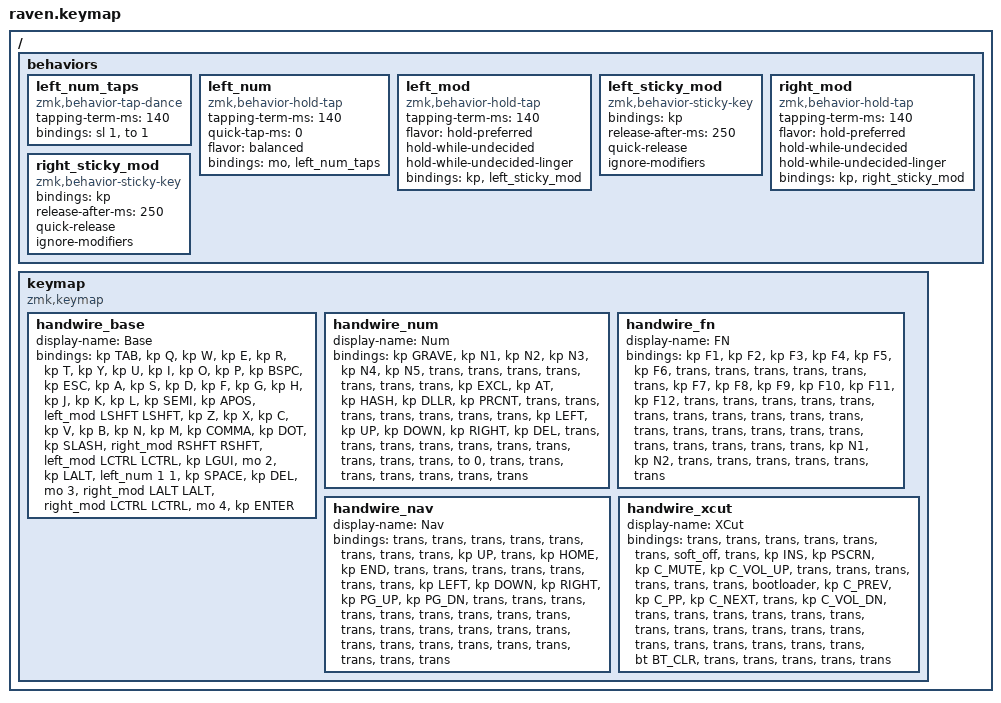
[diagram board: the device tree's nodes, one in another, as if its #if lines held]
#include <behaviors.dtsi>
#include <dt-bindings/zmk/keys.h>
#include <dt-bindings/zmk/bt.h>
#if defined(RAVEN_LEFT_HANDWIRE) || defined(RAVEN_RIGHT_HANDWIRE)
// Shared 4x12 handwire map: left central, right peripheral.
// Layers: Base=0, Num=1, FN=2, Nav=3, XCut=4.
/ {
    behaviors {
        left_num_taps: left_num_taps {
            compatible = "zmk,behavior-tap-dance";
            #binding-cells = <0>;
            tapping-term-ms = <140>;
            bindings = <&sl 1>, <&to 1>;
        };

        left_num: left_num {
            compatible = "zmk,behavior-hold-tap";
            #binding-cells = <2>;
            tapping-term-ms = <140>;
            quick-tap-ms = <0>;
            flavor = "balanced";
            bindings = <&mo>, <&left_num_taps>;
        };

        left_mod: left_mod {
            compatible = "zmk,behavior-hold-tap";
            #binding-cells = <2>;
            tapping-term-ms = <140>;
            flavor = "hold-preferred";
            hold-while-undecided;
            hold-while-undecided-linger;
            bindings = <&kp>, <&left_sticky_mod>;
        };

        left_sticky_mod: left_sticky_mod {
            compatible = "zmk,behavior-sticky-key";
            #binding-cells = <1>;
            bindings = <&kp>;
            release-after-ms = <250>;
            quick-release;
            ignore-modifiers;
        };

        right_mod: right_mod {
            compatible = "zmk,behavior-hold-tap";
            #binding-cells = <2>;
            tapping-term-ms = <140>;
            flavor = "hold-preferred";
            hold-while-undecided;
            hold-while-undecided-linger;
            bindings = <&kp>, <&right_sticky_mod>;
        };
        right_sticky_mod: right_sticky_mod {
            compatible = "zmk,behavior-sticky-key";
            #binding-cells = <1>;
            bindings = <&kp>;
            release-after-ms = <250>;
            quick-release;
            ignore-modifiers;
        };
    };
    keymap {
        compatible = "zmk,keymap";
        handwire_base {
            display-name = "Base";
            bindings = <
                &kp TAB   &kp Q   &kp W   &kp E   &kp R   &kp T     &kp Y   &kp U   &kp I   &kp O   &kp P   &kp BSPC
                &kp ESC   &kp A   &kp S   &kp D   &kp F   &kp G     &kp H   &kp J   &kp K   &kp L   &kp SEMI   &kp APOS
                &left_mod LSHFT LSHFT   &kp Z   &kp X   &kp C   &kp V   &kp B     &kp N   &kp M   &kp COMMA   &kp DOT   &kp SLASH   &right_mod RSHFT RSHFT
                &left_mod LCTRL LCTRL   &kp LGUI   &mo 2   &kp LALT   &left_num 1 1   &kp SPACE     &kp DEL   &mo 3   &right_mod LALT LALT   &right_mod LCTRL LCTRL   &mo 4   &kp ENTER
            >;
        };
        handwire_num {
            display-name = "Num";
            bindings = <
                &kp GRAVE   &kp N1   &kp N2   &kp N3   &kp N4   &kp N5     &trans   &trans   &trans   &trans   &trans   &trans
                &trans   &kp EXCL   &kp AT   &kp HASH   &kp DLLR   &kp PRCNT     &trans   &trans   &trans   &trans   &trans   &trans
                &trans   &kp LEFT   &kp UP   &kp DOWN   &kp RIGHT   &kp DEL     &trans   &trans   &trans   &trans   &trans   &trans
                &trans   &trans   &trans   &trans   &to 0   &trans     &trans   &trans   &trans   &trans   &trans   &trans
            >;
        };
        handwire_fn {
            display-name = "FN";
            bindings = <
                &kp F1   &kp F2   &kp F3   &kp F4   &kp F5   &kp F6     &trans   &trans   &trans   &trans   &trans   &trans
                &kp F7   &kp F8   &kp F9   &kp F10   &kp F11   &kp F12     &trans   &trans   &trans   &trans   &trans   &trans
                &trans   &trans   &trans   &trans   &trans   &trans     &trans   &trans   &trans   &trans   &trans   &trans
                &trans   &trans   &trans   &trans   &kp N1   &kp N2     &trans   &trans   &trans   &trans   &trans   &trans
            >;
        };
        handwire_nav {
            display-name = "Nav";
            bindings = <
                &trans   &trans   &trans   &trans   &trans   &trans     &trans   &trans   &kp UP   &trans   &kp HOME   &kp END
                &trans   &trans   &trans   &trans   &trans   &trans     &trans   &kp LEFT   &kp DOWN   &kp RIGHT   &kp PG_UP   &kp PG_DN
                &trans   &trans   &trans   &trans   &trans   &trans     &trans   &trans   &trans   &trans   &trans   &trans
                &trans   &trans   &trans   &trans   &trans   &trans     &trans   &trans   &trans   &trans   &trans   &trans
            >;
        };
        handwire_xcut {
            display-name = "XCut";
            bindings = <
                &trans   &trans   &trans   &trans   &trans   &trans     &soft_off   &trans   &kp INS   &kp PSCRN   &kp C_MUTE   &kp C_VOL_UP
                &trans   &trans   &trans   &trans   &trans   &trans     &bootloader   &kp C_PREV   &kp C_PP   &kp C_NEXT   &trans   &kp C_VOL_DN
                &trans   &trans   &trans   &trans   &trans   &trans     &trans   &trans   &trans   &trans   &trans   &trans
                &trans   &trans   &trans   &trans   &trans   &trans     &bt BT_CLR   &trans   &trans   &trans   &trans   &trans
            >;
        };
    };
};

#else
//https://zmk.dev/docs/keymaps/behaviors/sticky-key
/ {
    behaviors {
        hid_fwd: hid_fwd {
            compatible = "zmk,behavior-hid-fwd";
            label = "HID_FWD";
            #binding-cells = <0>;
        };
        mt: mod_tap {
            compatible = "zmk,behavior-hold-tap";
            #binding-cells = <2>;
            tapping-term-ms = <140>;
            bindings = <&kp>, <&skq>;
            flavor = "hold-preferred";
            hold-while-undecided;
            hold-while-undecided-linger;  // prevents shift release between hold and sticky
        };

        skq: sticky_key_quick_release {
            compatible = "zmk,behavior-sticky-key";
            #binding-cells = <1>;
            bindings = <&kp>;
            release-after-ms = <250>;
            quick-release;
            ignore-modifiers;
        };

        skl: sticky_key_lazy {
            compatible = "zmk,behavior-sticky-key";
            #binding-cells = <1>;
            bindings = <&kp>;
            release-after-ms = <250>;
            ignore-modifiers;
            lazy;
        };

        win_z: win_z_hold_tap {
            compatible = "zmk,behavior-hold-tap";
            label = "WIN_Z _HOLD_TAP";
            #binding-cells = <2>;
            tapping-term-ms = <140>; //hold timer to send hold key
            quick-tap-ms = <500>; //when tapped within timer, disable hold and send tap; for repeated presses
            require-prior-idle-ms = <250>; //When key press before timer, disable hold
            flavor = "tap-preferred";
            bindings = <&kp>, <&kp>;
        };

        not_so_sticky: not_so_sticky { //useful for combinations
            compatible = "zmk,behavior-sticky-key";
            label = "NOT_SO_STICKY";
            #binding-cells = <1>;
            bindings = <&mo>;
            release-after-ms = <800>;
            ignore-modifiers;
            //no 'quick-release' makes it linger even after a keypress
        };

        td_layer1: tap_dance_layer {
            compatible = "zmk,behavior-tap-dance";
            label = "TAP_DANCE_LAYER";
            #binding-cells = <0>;
            tapping-term-ms = <140>;
            bindings = <&sl 2>, <&to 2>;    // First tap = sticky layer 2, double tap = switch to layer 2
        };

        slmo1: sticky_momentary_layer {
            compatible = "zmk,behavior-hold-tap";
            label = "STICKY_MOMENTARY_LAYER";
            #binding-cells = <2>;
            tapping-term-ms = <140>;
            quick-tap-ms = <0>;
            flavor = "balanced";
            bindings = <&mo>, <&td_layer1>;  // Hold for momentary, tap for tap-dance behavior ex:&slmo 1 2
        };

        td_layer2: tap_dance_layer2 {
            compatible = "zmk,behavior-tap-dance";
            label = "TAP_DANCE_LAYER2";
            #binding-cells = <0>;
            tapping-term-ms = <140>;
            bindings = <&not_so_sticky 3>, <&to 3>;    // First tap = sticky layer 1, double tap = switch to layer 1
        };

        slmo2: sticky_momentary_layer2 {
            compatible = "zmk,behavior-hold-tap";
            label = "STICKY_MOMENTARY_LAYER2";
            #binding-cells = <2>;
            tapping-term-ms = <140>;
            quick-tap-ms = <0>;
            flavor = "balanced";
            bindings = <&mo>, <&td_layer2>;  // Hold for momentary, tap for tap-dance behavior ex:&slmo 1 2
        };

    };
    macros {
        sleep_macro: sleep_macro {
            compatible = "zmk,behavior-macro";
            #binding-cells = <0>;
            bindings
                = <&macro_press &kp LGUI>
                , <&macro_tap &kp X>
                , <&macro_release &kp LGUI>
                , <&macro_tap &kp U>
                , <&macro_tap &kp S>;
        };
    };
    combos {
        compatible = "zmk,combos";
        combo_esc {
            timeout-ms = <50>;
            key-positions = <0 1>; //TAB + Q
            bindings = <&kp ESC>;
            layers = <0 1 2 3 4>;
        };
        combo_capslock {
            timeout-ms = <50>;
            key-positions = <12 13>; // SHIFT + A
            bindings = <&kp CAPSLOCK>;
            layers = <0 1 2 3 4>;
        };
        layer_lock {
            timeout-ms = <50>;
            key-positions = <36 37>;   // ALT + NUM
            bindings = <&tog 2>;       // toggle layer 2
        };
        /*
        spc_del {
            timeout-ms = <50>;
            key-positions = <29 38>;   // B + SPC
            bindings = <&kp DEL>;
        };
        */
        xcut_layer {
            timeout-ms = <250>;
            key-positions = <34 35>;   // SLASH + LSHFT
            bindings = <&mo 5>;
        };

        alt_f4 {
            timeout-ms = <100>;
            require-prior-idle-ms = <100>; // Fix for "sticky" feeling; prevents combo if a key was pressed 150ms before
            key-positions = <36 16 3>;   // ALT + F + E    (ALT F + 4 hehe)
            bindings = <&kp LA(F4)>;  // Alt + F4 https://zmk.dev/docs/keymaps/modifiers
        };
    };

    keymap {
        compatible = "zmk,keymap";
        default_layer {
            display-name = "Base";
            bindings = <
                &kp TAB             &kp Q           &kp W       &kp E       &kp R       &kp T       &kp Y      &kp U        &kp I       &kp O       &kp P       &kp BSPC
                &mt LSHFT LSHFT     &kp A           &kp S       &kp D       &kp F       &kp G       &kp H      &kp J        &kp K       &kp L       &kp SEMI    &kp APOS
                &mt LCTRL LCTRL     &win_z LGUI Z   &kp X       &kp C       &kp V       &kp B       &kp N      &kp M        &kp COMMA   &kp DOT     &kp SLASH   &mt RSHFT RSHFT //used to be "mo 5"
                                                                &kp LALT    &slmo1 2 2  &kp SPACE   &kp DEL    &slmo2 4 4   &kp ENTER
            >;
        };
        // Layer 1 (Activated on Tap) Game layer, unused really. Remove?
        Game_layer {
            display-name = "Game";
            bindings = <
                &kp N1      &kp TAB         &kp Q       &kp W       &kp E       &kp R       &kp Y      &kp U        &kp I       &kp O       &kp P       &kp BSPC
                &kp N2      &kp LSHFT       &kp A       &kp S       &kp D       &kp F       &kp H      &kp J        &kp K       &kp L       &kp SEMI    &kp APOS
                &kp N3      &kp LCTRL       &kp Z       &kp X       &kp C       &kp V       &kp N      &kp M        &kp COMMA   &kp DOT     &kp SLASH   &to 0
                                                        &kp LALT    &mo 2       &kp SPACE   &kp DEL    &mo 4        &kp ENTER
            >;
        };
        // Layer 2 (Activated on hold)
        Num_layer {
            display-name = "Num";
            bindings = <
                &kp GRAVE       &kp N1      &kp N2      &kp N3      &kp N4      &kp N5      &kp N6      &kp N7      &kp N8      &kp N9      &kp N0      &kp BSPC
                &skl LSHFT      &kp EXCL    &kp AT      &kp HASH    &kp DLLR    &kp PRCNT   &kp CARET   &kp AMPS    &kp STAR    &kp LPAR    &kp RPAR    &kp MINUS
                &skl LCTRL      &kp LEFT    &kp UP      &kp DOWN    &kp RIGHT   &kp DEL     &kp LBKT    &kp RBKT    &trans      &trans      &kp BSLH    &kp EQUAL
                                                        &kp LALT    &to 0       &trans      &trans      &to 0       &trans
            >;
        };

        // Layer 3 (Activated on tap)
        F_keys {
            display-name = "FN";
            bindings = <
                &kp F1          &kp F2      &kp F3      &kp F4      &kp F5      &kp F6      &kp F7      &kp F8      &kp F9      &kp F10     &kp F11     &kp F12
                &trans          &trans      &trans      &trans      &trans      &trans      &trans      &trans      &trans      &trans      &trans      &trans
                &trans          &trans      &trans      &trans      &trans      &trans      &trans      &trans      &trans      &trans      &trans      &trans
                                                        &trans      &to 0       &trans      &kp K_APP   &to 0       &trans
            >;
        };

        // Layer 4 (Activated on hold)
        Nav_layer {
            display-name = "Nav";
            bindings = <
                &trans      &trans      &trans      &trans      &trans      &trans      &trans      &trans      &kp UP      &trans      &kp HOME       &kp END
                &trans      &trans      &trans      &trans      &trans      &trans      &trans      &kp LEFT    &kp DOWN    &kp RIGHT   &kp PG_UP      &kp PG_DN
                &trans      &trans      &trans      &trans      &trans      &trans      &trans      &trans      &trans      &trans      &trans         &trans
                                                    &trans      &trans      &trans      &trans      &trans      &trans
                >;
            };
        // Layer 5 (Activated on hold
        Shortcut_layer {
            display-name = "XCut";
            bindings = <
                &soft_off       &bt BT_SEL 0 &bt BT_SEL 1 &bt BT_SEL 2  &bt BT_SEL 3 &bt BT_SEL 4 &soft_off     &trans          &kp INS      &kp PSCRN       &kp C_MUTE    &kp C_VOL_UP
                &bootloader     &trans      &sleep_macro    &trans      &trans      &to 1       &bootloader     &kp C_PREV      &kp C_PP     &kp C_NEXT      &trans        &kp C_VOL_DN
                &trans          &trans      &trans          &trans      &trans      &trans      &trans          &trans          &trans       &trans          &trans        &trans
                                                            &trans      &trans      &trans      &bt BT_CLR      &trans          &trans
            >;
        };
    };
};

&soft_off {
    hold-time-ms = <50>; // 'fix' for peripheral not catching sleep command sometimes
    split-peripheral-off-on-press; // peripheral sleeps first, then central after delay
};
#endif
